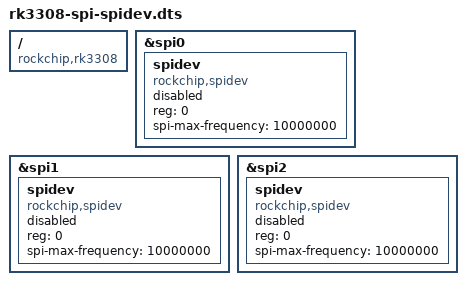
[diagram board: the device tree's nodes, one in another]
/dts-v1/;
/plugin/;

/ {
	compatible = "rockchip,rk3308";

	fragment@0 {
		target = <&spi0>;
		__overlay__ {
			#address-cells = <1>;
			#size-cells = <0>;
			spidev {
				compatible = "rockchip,spidev";
				status = "disabled";
				reg = <0>;
				spi-max-frequency = <10000000>;
			};
		};
	};

	fragment@1 {
		target = <&spi1>;
		__overlay__ {
			#address-cells = <1>;
			#size-cells = <0>;
			spidev {
				compatible = "rockchip,spidev";
				status = "disabled";
				reg = <0>;
				spi-max-frequency = <10000000>;
			};
		};
	};

	fragment@2 {
		target = <&spi2>;
		__overlay__ {
			#address-cells = <1>;
			#size-cells = <0>;
			spidev {
				compatible = "rockchip,spidev";
				status = "disabled";
				reg = <0>;
				spi-max-frequency = <10000000>;
			};
		};
	};
};
